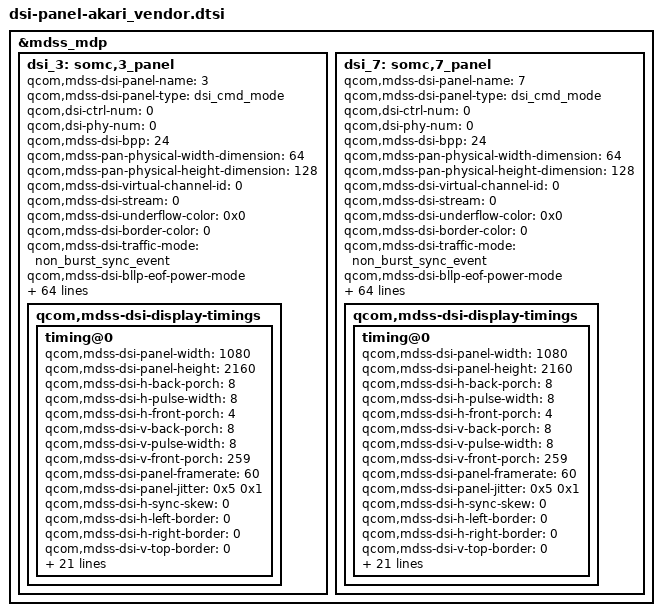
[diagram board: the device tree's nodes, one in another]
// SPDX-License-Identifier: GPL-2.0-only
/*
 * Copyright (c) 2015-2017, The Linux Foundation. All rights reserved.
 */

&mdss_mdp {
	/* Akari JDI ID3 */
	dsi_3: somc,3_panel {
		qcom,mdss-dsi-panel-name = "3";
		qcom,mdss-dsi-panel-type = "dsi_cmd_mode";

		qcom,dsi-ctrl-num = <0>;
		qcom,dsi-phy-num = <0>;

		qcom,mdss-dsi-bpp = <24>;
		qcom,mdss-pan-physical-width-dimension = <64>;
		qcom,mdss-pan-physical-height-dimension = <128>;
		qcom,mdss-dsi-virtual-channel-id = <0>;
		qcom,mdss-dsi-stream = <0>;
		qcom,mdss-dsi-underflow-color = <0x0>;
		qcom,mdss-dsi-border-color = <0>;
		qcom,mdss-dsi-traffic-mode = "non_burst_sync_event";
		qcom,mdss-dsi-bllp-eof-power-mode;
		qcom,mdss-dsi-bllp-power-mode;
		qcom,mdss-dsi-dma-trigger = "trigger_sw";
		qcom,mdss-dsi-mdp-trigger = "none";
		qcom,mdss-dsi-tx-eot-append;
		qcom,mdss-dsi-te-pin-select = <1>;
		qcom,mdss-dsi-wr-mem-start = <0x2c>;
		qcom,mdss-dsi-wr-mem-continue = <0x3c>;
		qcom,mdss-dsi-te-dcs-command = <1>;
		qcom,mdss-dsi-te-check-enable;
		qcom,mdss-dsi-te-using-te-pin;
		qcom,mdss-dsi-lane-0-state;
		qcom,mdss-dsi-lane-1-state;
		qcom,mdss-dsi-lane-2-state;
		qcom,mdss-dsi-lane-3-state;
		qcom,mdss-dsi-t-clk-post = <0x0E>;
		qcom,mdss-dsi-t-clk-pre = <0x33>;
		qcom,mdss-dsi-lp11-init;
		qcom,mdss-dsi-bl-min-level = <1>;
		qcom,mdss-dsi-bl-max-level = <4095>;
		qcom,mdss-brightness-max-level = <4095>;
		qcom,mdss-dsi-bl-pmic-control-type = "bl_ctrl_wled";

		qcom,mdss-dsi-panel-hdr-enabled;
		qcom,mdss-dsi-panel-hdr-color-primaries = <14500 15500 32000 17000 15500 30000 8000 3000>;
		qcom,mdss-dsi-panel-peak-brightness = <4200000>;
		qcom,mdss-dsi-panel-blackness-level = <3230>;

		qcom,mdss-dsi-reset-sequence = <1 50>;
		somc,mdss-dsi-touch-reset-sequence = <1 0>;
		somc,pw-on-rst-seq = "after_power_on";
		somc,dsi-panel-type = "lcd";
		somc,mdss-dsi-master;
		somc,pw-off-rst-b-seq = <0 0>;
		somc,pw-wait-after-on-vdd = <0>;
		somc,pw-wait-after-on-vddio = <0>;
		somc,pw-wait-after-on-vsp = <8>;
		somc,pw-wait-after-on-vsn = <0>;
		somc,pw-wait-after-off-vdd = <0>;
		somc,pw-wait-after-off-vddio = <0>;
		somc,pw-wait-after-off-vsp = <5>;
		somc,pw-wait-after-off-vsn = <8>;
		somc,pw-wait-after-on-touch-avdd = <0>;
		somc,pw-wait-after-on-touch-vddio = <0>;
		somc,pw-wait-after-on-touch-reset = <5>;
		somc,pw-wait-after-on-touch-int-n = <5>;
		somc,pw-wait-after-off-touch-avdd = <0>;
		somc,pw-wait-after-off-touch-vddio = <0>;
		somc,pw-wait-after-off-touch-reset = <5>;
		somc,pw-wait-after-off-touch-int-n = <0>;
		somc,pw-down-period = <100>;
		somc,lab-output-voltage = <5500000>;
		somc,ibb-output-voltage = <5500000>;

		somc,lcd-id-adc = <1236000 1395000>;

		somc,qpnp-lab-limit-maximum-current = <200>;
		somc,qpnp-ibb-limit-maximum-current = <800>;
		somc,qpnp-lab-max-precharge-time = <500>;
		somc,qpnp-lab-soft-start = <800>;
		somc,qpnp-ibb-discharge-resistor = <300>;
		somc,qpnp-lab-pull-down-enable;
		somc,qpnp-lab-full-pull-down;
		somc,qpnp-ibb-pull-down-enable;
		somc,qpnp-ibb-full-pull-down;

		somc,fps-mode-enable;
		somc,fps-mode-panel-mode = "dynamic_mode";

		qcom,mdss-dsi-display-timings {
			timing@0 {
				qcom,mdss-dsi-panel-width = <1080>;
				qcom,mdss-dsi-panel-height = <2160>;
				qcom,mdss-dsi-h-back-porch = <8>;
				qcom,mdss-dsi-h-pulse-width = <8>;
				qcom,mdss-dsi-h-front-porch = <4>;
				qcom,mdss-dsi-v-back-porch = <8>;
				qcom,mdss-dsi-v-pulse-width = <8>;
				qcom,mdss-dsi-v-front-porch = <259>;
				qcom,mdss-dsi-panel-framerate = <60>;
				qcom,mdss-dsi-panel-jitter = <0x5 0x1>;
				qcom,mdss-dsi-h-sync-skew = <0>;
				qcom,mdss-dsi-h-left-border = <0>;
				qcom,mdss-dsi-h-right-border = <0>;
				qcom,mdss-dsi-v-top-border = <0>;
				qcom,mdss-dsi-v-bottom-border = <0>;
				qcom,mdss-dsi-h-sync-pulse = <1>;
				qcom,mdss-dsi-on-command = [
						39 01 00 00 00 00 05 2A 00 00 04 37
						39 01 00 00 00 00 05 2B 00 00 08 6F
						39 01 00 00 00 00 03 44 00 00
						15 01 00 00 00 00 02 35 00
						15 01 00 00 00 00 02 36 00
						15 01 00 00 00 00 02 3A 77
						39 01 00 00 00 00 05 30 00 00 08 6F
						05 01 00 00 46 00 01 11];
				qcom,mdss-dsi-post-panel-on-command = [
						39 01 00 00 00 00 01 2C
						05 01 00 00 00 00 01 29];
				qcom,mdss-dsi-off-command = [
						05 01 00 00 16 00 01 28
						05 01 00 00 00 00 01 34
						05 01 00 00 50 00 01 10];
				qcom,mdss-dsi-on-command-state = "dsi_lp_mode";
				qcom,mdss-dsi-off-command-state = "dsi_hs_mode";
				qcom,mdss-dsi-panel-timings = [00 21 08 08 25 23 08 08 06 03 04 00];

				qcom,mdss-dsi-panel-clockrate = <964260000>;

				somc,fps-mode-off-rr-off = [
						23 01 00 00 00 00 02 B0 00
						29 01 00 00 00 00 05 B4 00 00 00 11
						23 01 00 00 00 00 02 B0 03];
				somc,fps-mode-off-rr-on = [
						23 01 00 00 00 00 02 B0 00
						29 01 00 00 00 00 05 B4 00 00 00 11
						23 01 00 00 00 00 02 B0 03];
				somc,fps-mode-on-rr-off = [
						23 01 00 00 00 00 02 B0 00
						29 01 00 00 00 00 05 B4 00 01 00 11
						23 01 00 00 00 00 02 B0 03];
				somc,fps-mode-on-rr-on = [
						23 01 00 00 00 00 02 B0 00
						29 01 00 00 00 00 05 B4 00 01 00 11
						23 01 00 00 00 00 02 B0 03];
			};
		};
	};

	/* Akari LGD ID7 */
	dsi_7: somc,7_panel {
		qcom,mdss-dsi-panel-name = "7";
		qcom,mdss-dsi-panel-type = "dsi_cmd_mode";

		qcom,dsi-ctrl-num = <0>;
		qcom,dsi-phy-num = <0>;

		qcom,mdss-dsi-bpp = <24>;
		qcom,mdss-pan-physical-width-dimension = <64>;
		qcom,mdss-pan-physical-height-dimension = <128>;
		qcom,mdss-dsi-virtual-channel-id = <0>;
		qcom,mdss-dsi-stream = <0>;
		qcom,mdss-dsi-underflow-color = <0x0>;
		qcom,mdss-dsi-border-color = <0>;
		qcom,mdss-dsi-traffic-mode = "non_burst_sync_event";
		qcom,mdss-dsi-bllp-eof-power-mode;
		qcom,mdss-dsi-bllp-power-mode;
		qcom,mdss-dsi-dma-trigger = "trigger_sw";
		qcom,mdss-dsi-mdp-trigger = "none";
		qcom,mdss-dsi-tx-eot-append;
		qcom,mdss-dsi-te-pin-select = <1>;
		qcom,mdss-dsi-wr-mem-start = <0x2c>;
		qcom,mdss-dsi-wr-mem-continue = <0x3c>;
		qcom,mdss-dsi-te-dcs-command = <1>;
		qcom,mdss-dsi-te-check-enable;
		qcom,mdss-dsi-te-using-te-pin;
		qcom,mdss-dsi-lane-0-state;
		qcom,mdss-dsi-lane-1-state;
		qcom,mdss-dsi-lane-2-state;
		qcom,mdss-dsi-lane-3-state;
		qcom,mdss-dsi-t-clk-post = <0x0E>;
		qcom,mdss-dsi-t-clk-pre = <0x33>;
		qcom,mdss-dsi-lp11-init;
		qcom,mdss-dsi-bl-min-level = <1>;
		qcom,mdss-dsi-bl-max-level = <4095>;
		qcom,mdss-brightness-max-level = <4095>;
		qcom,mdss-dsi-bl-pmic-control-type = "bl_ctrl_wled";

		qcom,mdss-dsi-panel-hdr-enabled;
		qcom,mdss-dsi-panel-hdr-color-primaries = <14500 15500 32000 17000 15500 30000 8000 3000>;
		qcom,mdss-dsi-panel-peak-brightness = <4200000>;
		qcom,mdss-dsi-panel-blackness-level = <3230>;

		qcom,mdss-dsi-reset-sequence = <1 0>;
		somc,mdss-dsi-touch-reset-sequence = <1 5>;
		somc,pw-on-rst-seq = "before_power_on";
		somc,dsi-panel-type = "lcd";
		somc,mdss-dsi-master;
		somc,pw-off-rst-b-seq = <0 5>;
		somc,pw-wait-after-on-vdd = <0>;
		somc,pw-wait-after-on-vddio = <0>;
		somc,pw-wait-after-on-vsp = <8>;
		somc,pw-wait-after-on-vsn = <17>;
		somc,pw-wait-after-off-vdd = <0>;
		somc,pw-wait-after-off-vddio = <0>;
		somc,pw-wait-after-off-vsp = <10>;
		somc,pw-wait-after-off-vsn = <8>;
		somc,pw-wait-after-on-touch-avdd = <0>;
		somc,pw-wait-after-on-touch-vddio = <0>;
		somc,pw-wait-after-on-touch-reset = <5>;
		somc,pw-wait-after-on-touch-int-n = <5>;
		somc,pw-wait-after-off-touch-avdd = <0>;
		somc,pw-wait-after-off-touch-vddio = <0>;
		somc,pw-wait-after-off-touch-reset = <5>;
		somc,pw-wait-after-off-touch-int-n = <0>;
		somc,pw-down-period = <100>;
		somc,lab-output-voltage = <5600000>;
		somc,ibb-output-voltage = <5500000>;

		somc,lcd-id-adc = <353000 414000>;

		somc,qpnp-lab-limit-maximum-current = <200>;
		somc,qpnp-ibb-limit-maximum-current = <800>;
		somc,qpnp-lab-max-precharge-time = <500>;
		somc,qpnp-lab-soft-start = <800>;
		somc,qpnp-ibb-discharge-resistor = <300>;
		somc,qpnp-lab-pull-down-enable;
		somc,qpnp-lab-full-pull-down;
		somc,qpnp-ibb-pull-down-enable;
		somc,qpnp-ibb-full-pull-down;

		somc,fps-mode-enable;
		somc,fps-mode-panel-mode = "dynamic_mode";

		qcom,mdss-dsi-display-timings {
			timing@0 {
				qcom,mdss-dsi-panel-width = <1080>;
				qcom,mdss-dsi-panel-height = <2160>;
				qcom,mdss-dsi-h-back-porch = <8>;
				qcom,mdss-dsi-h-pulse-width = <8>;
				qcom,mdss-dsi-h-front-porch = <4>;
				qcom,mdss-dsi-v-back-porch = <8>;
				qcom,mdss-dsi-v-pulse-width = <8>;
				qcom,mdss-dsi-v-front-porch = <259>;
				qcom,mdss-dsi-panel-framerate = <60>;
				qcom,mdss-dsi-panel-jitter = <0x5 0x1>;
				qcom,mdss-dsi-h-sync-skew = <0>;
				qcom,mdss-dsi-h-left-border = <0>;
				qcom,mdss-dsi-h-right-border = <0>;
				qcom,mdss-dsi-v-top-border = <0>;
				qcom,mdss-dsi-v-bottom-border = <0>;
				qcom,mdss-dsi-h-sync-pulse = <1>;
				qcom,mdss-dsi-on-command = [
						39 01 00 00 00 00 05 2A 00 00 04 37
						39 01 00 00 00 00 05 2B 00 00 08 6F
						15 01 00 00 00 00 02 35 00];
				qcom,mdss-dsi-post-panel-on-command = [
						05 01 00 00 00 00 01 29
						05 01 00 00 46 00 01 11];
				qcom,mdss-dsi-off-command = [
						05 01 00 00 00 00 01 28
						05 01 00 00 55 00 01 10];
				qcom,mdss-dsi-on-command-state = "dsi_lp_mode";
				qcom,mdss-dsi-off-command-state = "dsi_hs_mode";
				qcom,mdss-dsi-panel-timings = [00 21 08 08 25 23 08 08 06 03 04 00];

				qcom,mdss-dsi-panel-clockrate = <964260000>;

				somc,fps-mode-off-rr-off = [
						29 01 00 00 00 00 02 B0 00
						29 01 00 00 00 00 0B E7 50 00 00 00 00 00 00 00 00 00
						29 01 00 00 00 00 02 B0 03];
				somc,fps-mode-off-rr-on = [
						29 01 00 00 00 00 02 B0 00
						29 01 00 00 00 00 0B E7 50 00 00 00 00 00 00 00 00 00
						29 01 00 00 00 00 02 B0 03];
				somc,fps-mode-on-rr-off = [
						29 01 00 00 00 00 02 B0 00
						29 01 00 00 00 00 0B C0 CE CE 08 08 70 00 05 00 01 BB
						29 01 00 00 00 00 46 C3 00 00 00 00 00 00 00 00 00 00 00 00 00 00 00 00 00 00 00 00 00 00 00 00 00 00 00 00 00 00 00 00 08 00 08 00 08 00 00 00 A0 00 08 00 08 00 08 00 00 00 A0 00 08 00 08 00 08 00 00 00 A0 00 00 00 00 00 00 00 00
						29 01 00 00 00 00 1E EA 01 0C 0B 40 0B 40 00 00 05 00 03 B0 0D 0B 40 0B 40 00 00 00 05 5E 00 11 00 CE 0C E0 CE
						29 01 00 00 00 00 21 ED 01 01 02 02 07 08 08 09 00 00 00 00 01 00 00 00 00 10 00 18 00 18 00 B0 00 00 18 00 18 D0 10 00
						29 01 00 00 00 00 0B E7 51 00 00 00 00 00 00 00 00 00
						29 01 00 00 00 00 02 B0 03];
				somc,fps-mode-on-rr-on = [
						29 01 00 00 00 00 02 B0 00
						29 01 00 00 00 00 0B C0 CE CE 08 08 70 00 05 00 01 BB
						29 01 00 00 00 00 46 C3 00 00 00 00 00 00 00 00 00 00 00 00 00 00 00 00 00 00 00 00 00 00 00 00 00 00 00 00 00 00 00 00 08 00 08 00 08 00 00 00 A0 00 08 00 08 00 08 00 00 00 A0 00 08 00 08 00 08 00 00 00 A0 00 00 00 00 00 00 00 00
						29 01 00 00 00 00 1E EA 01 0C 0B 40 0B 40 00 00 05 00 03 B0 0D 0B 40 0B 40 00 00 00 05 5E 00 11 00 CE 0C E0 CE
						29 01 00 00 00 00 21 ED 01 01 02 02 07 08 08 09 00 00 00 00 01 00 00 00 00 10 00 18 00 18 00 B0 00 00 18 00 18 D0 10 00
						29 01 00 00 00 00 0B E7 51 00 00 00 00 00 00 00 00 00
						29 01 00 00 00 00 02 B0 03];
			};
		};
	};
};

#include "dsi-panel-akari-id3_pcc.dtsi"
#include "dsi-panel-akari-id7_pcc.dtsi"
